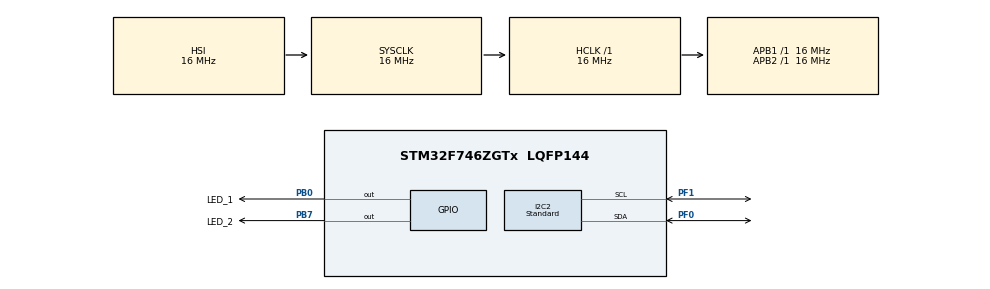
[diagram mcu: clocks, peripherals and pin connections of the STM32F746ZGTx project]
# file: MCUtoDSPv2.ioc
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CORTEX_M7.default_mode_Activation=1
I2C2.DualAddressMode=I2C_DUALADDRESS_DISABLE
I2C2.GeneralCallMode=I2C_GENERALCALL_DISABLE
I2C2.I2C_Speed_Mode=I2C_Standard
I2C2.NoStretchMode=I2C_NOSTRETCH_DISABLE
I2C2.Speed=100
I2C2.Timing=0x00303D5B
Mcu.Family=STM32F7
Mcu.Name=STM32F746ZGTx
Mcu.Package=LQFP144
NVIC.PriorityGroup=NVIC_PRIORITYGROUP_4
PB0.GPIO_Label=LED_1
PB0.Signal=GPIO_Output
PB7.GPIO_Label=LED_2
PB7.Signal=GPIO_Output
PF0.GPIO_Pu=GPIO_PULLUP
PF0.Mode=I2C
PF0.Signal=I2C2_SDA
PF1.GPIO_Pu=GPIO_PULLUP
PF1.Mode=I2C
PF1.Signal=I2C2_SCL
PH0/OSC_IN.Mode=HSE-External-Oscillator
PH0/OSC_IN.Signal=RCC_OSC_IN
PH1/OSC_OUT.Mode=HSE-External-Oscillator
PH1/OSC_OUT.Signal=RCC_OSC_OUT
ProjectManager.HeapSize=0x200
ProjectManager.StackSize=0x400
ProjectManager.TargetToolchain=STM32CubeIDE
RCC.AHBFreq_Value=16000000
RCC.APB1Freq_Value=16000000
RCC.APB1TimFreq_Value=16000000
RCC.APB2Freq_Value=16000000
RCC.APB2TimCLKDivider=1
RCC.APB2TimFreq_Value=16000000
RCC.CortexFreq_Value=16000000
RCC.HCLKFreq_Value=16000000
RCC.HSE_VALUE=25000000
RCC.HSI_VALUE=16000000
RCC.LSE_VALUE=32768
RCC.SYSCLKFreq_VALUE=16000000
RCC.USBFreq_Value=96000000
RCC.VCOOutputFreq_Value=192000000
board=custom

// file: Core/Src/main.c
/* USER CODE BEGIN Header */
/**
  ******************************************************************************
  * @file           : main.c
  * @brief          : Main program body
  ******************************************************************************
  * @attention
  *
  * Copyright (c) 2024 STMicroelectronics.
  * All rights reserved.
  *
  * This software is licensed under terms that can be found in the LICENSE file
  * in the root directory of this software component.
  * If no LICENSE file comes with this software, it is provided AS-IS.
  *
  ******************************************************************************
  */
/* USER CODE END Header */
#include "main.h"

I2C_HandleTypeDef hi2c2;

void SystemClock_Config(void);
static void MPU_Config(void);
static void MX_GPIO_Init(void);
static void MX_I2C2_Init(void);

/* USER CODE BEGIN 0 */
#include "../Inc/Exports/DSP_2024_05_13_IC_1.h"
#include "DSPtoMCU.h"
/* USER CODE END 0 */

int main(void)
{

  /* MPU Configuration--------------------------------------------------------*/
  MPU_Config();

  /* MCU Configuration--------------------------------------------------------*/

  /* Reset of all peripherals, Initializes the Flash interface and the Systick. */
  HAL_Init();

  /* Configure the system clock */
  SystemClock_Config();

  /* Initialize all configured peripherals */
  MX_GPIO_Init();
  MX_I2C2_Init();
  /* USER CODE BEGIN 2 */

  default_download_IC_1();
  DSP_TONE1_CHANGE_FREQUENCY(600);

  /* USER CODE END 2 */

  /* Infinite loop */
  while (1)
  {

  }
}

void SystemClock_Config(void)
{
  RCC_OscInitTypeDef RCC_OscInitStruct = {0};
  RCC_ClkInitTypeDef RCC_ClkInitStruct = {0};

  /** Configure the main internal regulator output voltage
  */
  __HAL_RCC_PWR_CLK_ENABLE();
  __HAL_PWR_VOLTAGESCALING_CONFIG(PWR_REGULATOR_VOLTAGE_SCALE3);

  /** Initializes the RCC Oscillators according to the specified parameters
  * in the RCC_OscInitTypeDef structure.
  */
  RCC_OscInitStruct.OscillatorType = RCC_OSCILLATORTYPE_HSI;
  RCC_OscInitStruct.HSIState = RCC_HSI_ON;
  RCC_OscInitStruct.HSICalibrationValue = RCC_HSICALIBRATION_DEFAULT;
  RCC_OscInitStruct.PLL.PLLState = RCC_PLL_NONE;
  if (HAL_RCC_OscConfig(&RCC_OscInitStruct) != HAL_OK)
  {
    Error_Handler();
  }

  /** Initializes the CPU, AHB and APB buses clocks
  */
  RCC_ClkInitStruct.ClockType = RCC_CLOCKTYPE_HCLK|RCC_CLOCKTYPE_SYSCLK
                              |RCC_CLOCKTYPE_PCLK1|RCC_CLOCKTYPE_PCLK2;
  RCC_ClkInitStruct.SYSCLKSource = RCC_SYSCLKSOURCE_HSI;
  RCC_ClkInitStruct.AHBCLKDivider = RCC_SYSCLK_DIV1;
  RCC_ClkInitStruct.APB1CLKDivider = RCC_HCLK_DIV1;
  RCC_ClkInitStruct.APB2CLKDivider = RCC_HCLK_DIV1;

  if (HAL_RCC_ClockConfig(&RCC_ClkInitStruct, FLASH_LATENCY_0) != HAL_OK)
  {
    Error_Handler();
  }
}

static void MX_I2C2_Init(void)
{

  hi2c2.Instance = I2C2;
  hi2c2.Init.Timing = 0x00000107;
  hi2c2.Init.OwnAddress1 = 0;
  hi2c2.Init.AddressingMode = I2C_ADDRESSINGMODE_7BIT;
  hi2c2.Init.DualAddressMode = I2C_DUALADDRESS_DISABLE;
  hi2c2.Init.OwnAddress2 = 0;
  hi2c2.Init.OwnAddress2Masks = I2C_OA2_NOMASK;
  hi2c2.Init.GeneralCallMode = I2C_GENERALCALL_DISABLE;
  hi2c2.Init.NoStretchMode = I2C_NOSTRETCH_DISABLE;
  if (HAL_I2C_Init(&hi2c2) != HAL_OK)
  {
    Error_Handler();
  }

  /** Configure Analogue filter
  */
  if (HAL_I2CEx_ConfigAnalogFilter(&hi2c2, I2C_ANALOGFILTER_ENABLE) != HAL_OK)
  {
    Error_Handler();
  }

  /** Configure Digital filter
  */
  if (HAL_I2CEx_ConfigDigitalFilter(&hi2c2, 0) != HAL_OK)
  {
    Error_Handler();
  }

  /** I2C Enable Fast Mode Plus
  */
  HAL_I2CEx_EnableFastModePlus(I2C_FASTMODEPLUS_I2C2);

}

static void MX_GPIO_Init(void)
{
  GPIO_InitTypeDef GPIO_InitStruct = {0};

  /* GPIO Ports Clock Enable */
  __HAL_RCC_GPIOF_CLK_ENABLE();
  __HAL_RCC_GPIOH_CLK_ENABLE();
  __HAL_RCC_GPIOB_CLK_ENABLE();

  /*Configure GPIO pin Output Level */
  HAL_GPIO_WritePin(GPIOB, LED_1_Pin|LED_2_Pin, GPIO_PIN_RESET);

  /*Configure GPIO pins : LED_1_Pin LED_2_Pin */
  GPIO_InitStruct.Pin = LED_1_Pin|LED_2_Pin;
  GPIO_InitStruct.Mode = GPIO_MODE_OUTPUT_PP;
  GPIO_InitStruct.Pull = GPIO_NOPULL;
  GPIO_InitStruct.Speed = GPIO_SPEED_FREQ_LOW;
  HAL_GPIO_Init(GPIOB, &GPIO_InitStruct);

}

 /* MPU Configuration */

void MPU_Config(void)
{
  MPU_Region_InitTypeDef MPU_InitStruct = {0};

  /* Disables the MPU */
  HAL_MPU_Disable();

  /** Initializes and configures the Region and the memory to be protected
  */
  MPU_InitStruct.Enable = MPU_REGION_ENABLE;
  MPU_InitStruct.Number = MPU_REGION_NUMBER0;
  MPU_InitStruct.BaseAddress = 0x0;
  MPU_InitStruct.Size = MPU_REGION_SIZE_4GB;
  MPU_InitStruct.SubRegionDisable = 0x87;
  MPU_InitStruct.TypeExtField = MPU_TEX_LEVEL0;
  MPU_InitStruct.AccessPermission = MPU_REGION_NO_ACCESS;
  MPU_InitStruct.DisableExec = MPU_INSTRUCTION_ACCESS_DISABLE;
  MPU_InitStruct.IsShareable = MPU_ACCESS_SHAREABLE;
  MPU_InitStruct.IsCacheable = MPU_ACCESS_NOT_CACHEABLE;
  MPU_InitStruct.IsBufferable = MPU_ACCESS_NOT_BUFFERABLE;

  HAL_MPU_ConfigRegion(&MPU_InitStruct);
  /* Enables the MPU */
  HAL_MPU_Enable(MPU_PRIVILEGED_DEFAULT);

}

void Error_Handler(void)
{
  __disable_irq();
  while (1)
  {
  }
}
